# N32H7xx register map
Vendor: Nationstech Ltd.; File version: 1.0
CPU: CM7 r1p1, little endian, MPU, FPU, 4 interrupt priority bits
Registers are 32-bit, read-write, reset 0x0 unless marked. A register's access mark holds for its fields unless they carry their own. Offsets are from the block's base; [hi:lo] are bit positions.

## IWDG1 — Independent watchdog
Base 0x58004C00
Same registers: IWDG2 0x58005000
0x00 IWDG_KEY
  [15:0] KEYV
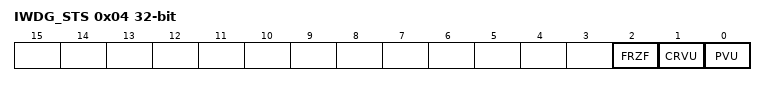
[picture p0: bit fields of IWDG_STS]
0x04 IWDG_STS ro (reset mask 0x3)
  [2] FRZF, [1] CRVU, [0] PVU
0x08 IWDG_PREDIV
  [2:0] PD
0x0C IWDG_RELV reset 0xFFF
  [11:0] REL

## WWDG1 — window watchdog
Base 0x5004A800
Same registers: WWDG2 0x40010000
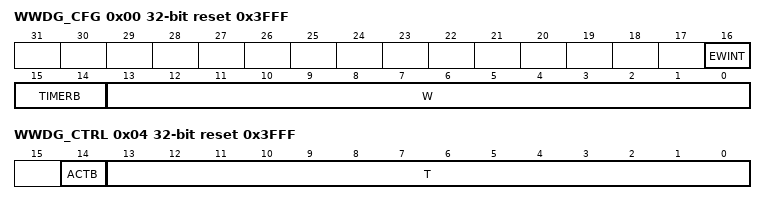
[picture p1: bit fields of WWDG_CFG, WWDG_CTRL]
0x00 WWDG_CFG reset 0x3FFF
  [16] EWINT, [15:14] TIMERB, [13:0] W
0x04 WWDG_CTRL reset 0x3FFF
  [14] ACTB, [13:0] T
0x08 WWDG_STS
  [0] EWINTF

## USART1
Base 0x4000C400
Same registers: USART2 0x4000C800, USART3 0x4000CC00, USART4 0x4000D000, UART9 0x4000D400, UART10 0x4000D800, UART11 0x4000DC00, UART12 0x4000E000, USART5 0x400DE000, USART6 0x400DE400, USART7 0x400DE800, USART8 0x400DEC00, UART13 0x400DF000, UART14 0x400DF400, UART15 0x400DF800
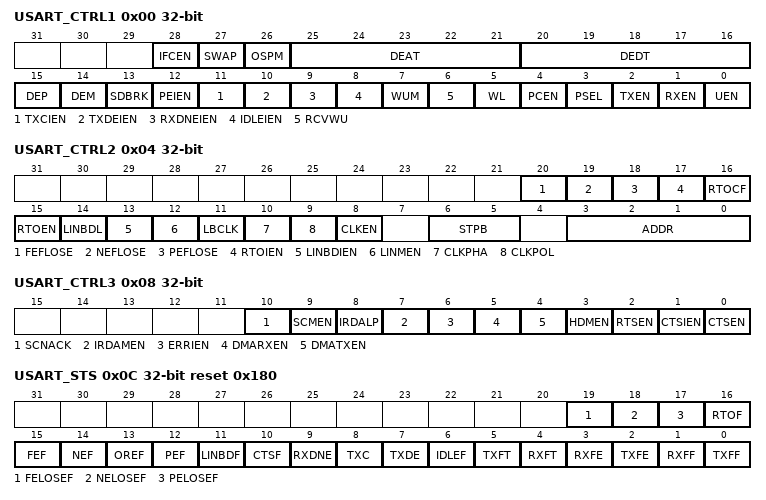
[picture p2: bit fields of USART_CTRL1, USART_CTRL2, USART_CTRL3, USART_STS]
0x00 USART_CTRL1
  [28] IFCEN, [27] SWAP, [26] OSPM, [25:21] DEAT, [20:16] DEDT, [15] DEP, [14] DEM, [13] SDBRK, [12] PEIEN, [11] TXCIEN, [10] TXDEIEN, [9] RXDNEIEN, [8] IDLEIEN, [7] WUM, [6] RCVWU, [5] WL, [4] PCEN, [3] PSEL, [2] TXEN, [1] RXEN, [0] UEN
0x04 USART_CTRL2
  [20] FEFLOSE, [19] NEFLOSE, [18] PEFLOSE, [17] RTOIEN, [16] RTOCF, [15] RTOEN, [14] LINBDL, [13] LINBDIEN, [12] LINMEN, [11] LBCLK, [10] CLKPHA, [9] CLKPOL, [8] CLKEN, [6:5] STPB, [3:0] ADDR
0x08 USART_CTRL3
  [10] SCNACK, [9] SCMEN, [8] IRDALP, [7] IRDAMEN, [6] ERRIEN, [5] DMARXEN, [4] DMATXEN, [3] HDMEN, [2] RTSEN, [1] CTSIEN, [0] CTSEN
0x0C USART_STS reset 0x180
  [19] FELOSEF, [18] NELOSEF, [17] PELOSEF, [16] RTOF ro, [15] FEF ro, [14] NEF ro, [13] OREF ro, [12] PEF ro, [11] LINBDF, [10] CTSF, [9] RXDNE, [8] TXC, [7] TXDE ro, [6] IDLEF ro, [5] TXFT ro, [4] RXFT ro, [3] RXFE ro, [2] TXFE ro, [1] RXFF ro, [0] TXFF ro
0x10 USART_DAT
  [8:0] DATV
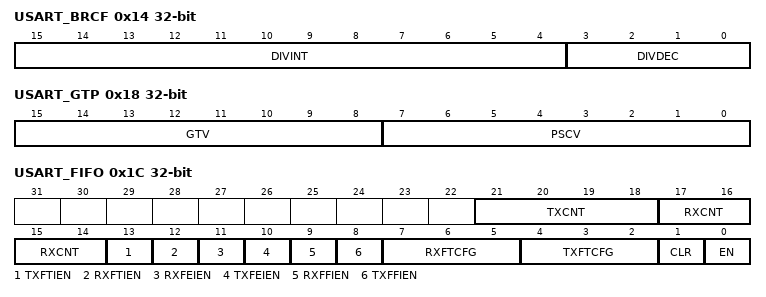
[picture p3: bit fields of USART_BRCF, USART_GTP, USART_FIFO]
0x14 USART_BRCF
  [15:4] DIVINT, [3:0] DIVDEC
0x18 USART_GTP
  [15:8] GTV, [7:0] PSCV
0x1C USART_FIFO
  [21:18] TXCNT ro, [17:14] RXCNT ro, [13] TXFTIEN, [12] RXFTIEN, [11] RXFEIEN, [10] TXFEIEN, [9] RXFFIEN, [8] TXFFIEN, [7:5] RXFTCFG, [4:2] TXFTCFG, [1] CLR, [0] EN
0x20 USART_IFW
  [15:0] WIDTH
0x24 USART_RTO
  [27:0] TIME

## LPUART1 — Low-power universal asynchronous receiver transmitter
Base 0x58000800
Same registers: LPUART2 0x58000C00
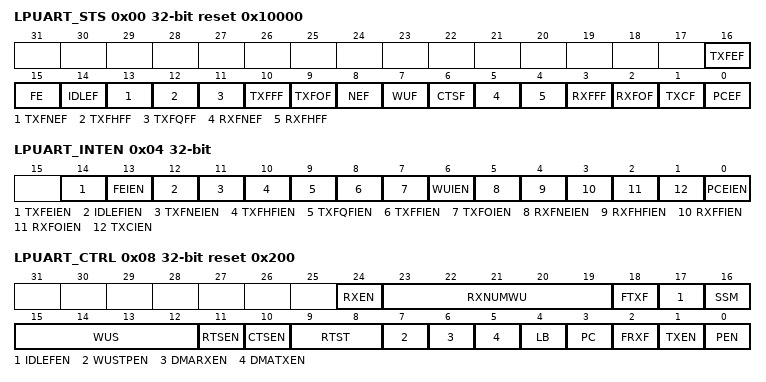
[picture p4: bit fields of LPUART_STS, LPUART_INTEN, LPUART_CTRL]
0x00 LPUART_STS reset 0x10000
  [16] TXFEF ro, [15] FE, [14] IDLEF, [13] TXFNEF, [12] TXFHFF, [11] TXFQFF, [10] TXFFF, [9] TXFOF, [8] NEF, [7] WUF, [6] CTSF ro, [5] RXFNEF, [4] RXFHFF, [3] RXFFF, [2] RXFOF, [1] TXCF, [0] PCEF
0x04 LPUART_INTEN
  [14] TXFEIEN, [13] FEIEN, [12] IDLEFIEN, [11] TXFNEIEN, [10] TXFHFIEN, [9] TXFQFIEN, [8] TXFFIEN, [7] TXFOIEN, [6] WUIEN, [5] RXFNEIEN, [4] RXFHFIEN, [3] RXFFIEN, [2] RXFOIEN, [1] TXCIEN, [0] PCEIEN
0x08 LPUART_CTRL reset 0x200
  [24] RXEN, [23:19] RXNUMWU, [18] FTXF, [17] IDLEFEN, [16] SSM, [15:12] WUS, [11] RTSEN, [10] CTSEN, [9:8] RTST, [7] WUSTPEN, [6] DMARXEN, [5] DMATXEN, [4] LB, [3] PC, [2] FRXF, [1] TXEN, [0] PEN
0x0C LPUART_BRCFG1 reset 0x174
  [15:0] BRP
0x10 LPUART_TXDAT
  [7:0] DAT
0x14 LPUART_BRCFG2
  [7:0] MC
0x18 LPUART_WUDAT1
  [31:0] DAT
0x1C LPUART_WUDAT2
  [31:0] DAT
0x20 LPUART_RXDAT ro
  [7:0] DAT

## FMAC — Filter math accelerator
Base 0x400F1400
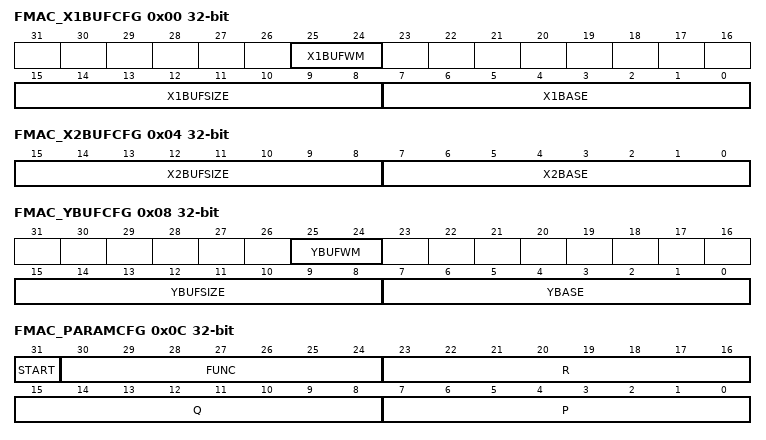
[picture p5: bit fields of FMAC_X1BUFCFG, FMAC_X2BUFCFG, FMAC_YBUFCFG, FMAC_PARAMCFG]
0x00 FMAC_X1BUFCFG — FMAC X1 Buffer Configuration Register
  [25:24] X1BUFWM — X1 buffer watermark size
  [15:8] X1BUFSIZE — X1 buffer size
  [7:0] X1BASE — X1 buffer base address
0x04 FMAC_X2BUFCFG — FMAC X2 Buffer Configuration Register
  [15:8] X2BUFSIZE — X2 buffer size
  [7:0] X2BASE — X2 buffer base address
0x08 FMAC_YBUFCFG — FMAC Y Buffer Configuration Register
  [25:24] YBUFWM — Y buffer watermark size
  [15:8] YBUFSIZE — Y buffer size
  [7:0] YBASE — Y buffer base address
0x0C FMAC_PARAMCFG — FMAC Parameter Configuration Register
  [31] START — Enable execution
  [30:24] FUNC — Function
  [23:16] R — Input parameter R
  [15:8] Q — Input parameter Q
  [7:0] P — Input parameter P
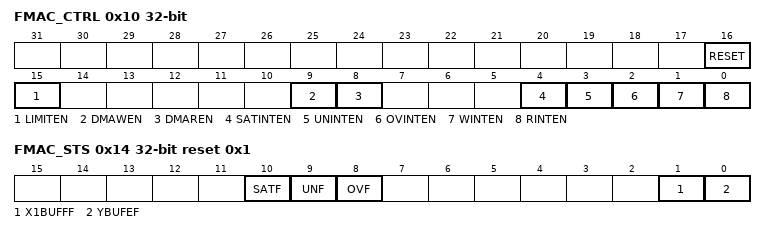
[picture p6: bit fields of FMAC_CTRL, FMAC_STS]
0x10 FMAC_CTRL — FMAC Control Register
  [16] RESET — Reset FMAC
  [15] LIMITEN — Clipping enable
  [9] DMAWEN — Enable DMA write channel request
  [8] DMAREN — Enable DMA read channel request
  [4] SATINTEN — Saturation error interrupt enable
  [3] UNINTEN — Underflow error interrupt enable
  [2] OVINTEN — Overflow error interrupt enable
  [1] WINTEN — Write interrupt enable
  [0] RINTEN — Read interrupt enable
0x14 FMAC_STS ro reset 0x1 — FMAC Status Register
  [10] SATF — Saturation error flag
  [9] UNF — Underflow error flag
  [8] OVF — Overflow error flag
  [1] X1BUFFF — X1 buffer full flag
  [0] YBUFEF — Y buffer empty flag
0x18 FMAC_WDAT wo — FMAC Write Data Register
  [15:0] WDAT — Write data
0x1C FMAC_RDAT ro — FMAC Read Data Register
  [15:0] RDAT — Read data
